# STM32G414xx register map
File version: 1.0
Registers are 32-bit, read-write, reset 0x0 unless marked. A register's access mark holds for its fields unless they carry their own. Offsets are from the block's base; [hi:lo] are bit positions; {n}, {i} and the like mark numbered series.

## CRS — Clock Recovery System
Base 0x40002000
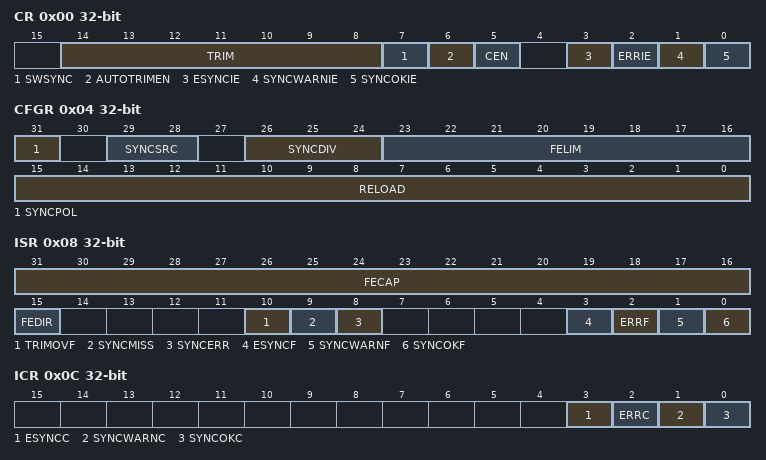
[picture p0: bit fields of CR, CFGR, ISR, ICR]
0x00 CR — CRS ccontrol register
  [14:8] TRIM — HSI48 oscillator smooth trimming
  [7] SWSYNC — Generate software SYNC event
  [6] AUTOTRIMEN — Automatic trimming enable
  [5] CEN — Frequency error counter enable
  [3] ESYNCIE — Expected SYNC interrupt enable
  [2] ERRIE — SYNC error or trimming error interrupt enable
  [1] SYNCWARNIE — SYNC warning interrupt enable
  [0] SYNCOKIE — SYNC event OK interrupt enable
0x04 CFGR — CRS configuration register
  [31] SYNCPOL — SYNC polarity selection
    0=RISING (Synchro Active on rising edge (default)); 1=FALLING (Synchro Active on falling edge)
  [29:28] SYNCSRC — SYNC signal source selection
    0=GPIO (Synchro Signal source GPIO); 1=LSE (Synchro Signal source LSE); 2=USB (Synchro Signal source USB SOF (default))
  [26:24] SYNCDIV — SYNC divider
    0=DIV_1 (Synchro Signal not divided (default)); 1=DIV_2 (Synchro Signal divided by 2); 2=DIV_4 (Synchro Signal divided by 4); 3=DIV_8 (Synchro Signal divided by 8); 4=DIV_16 (Synchro Signal divided by 16); 5=DIV_32 (Synchro Signal divided by 32); 6=DIV_64 (Synchro Signal divided by 64); 7=DIV_128 (Synchro Signal divided by 128)
  [23:16] FELIM — Frequency error limit
  [15:0] RELOAD — Counter reload value
0x08 ISR — CRS interrupt and status register
  [31:16] FECAP — Frequency error capture
  [15] FEDIR — Frequency error direction
    0=UP (Upcounting direction, the actual frequency is above the target); 1=DOWN (Downcounting direction, the actual frequency is below the target)
  [10] TRIMOVF — Trimming overflow or underflow
  [9] SYNCMISS — SYNC missed
  [8] SYNCERR — SYNC error
  [3] ESYNCF — Expected SYNC flag
  [2] ERRF — Error flag
  [1] SYNCWARNF — SYNC warning flag
  [0] SYNCOKF — SYNC event OK flag
0x0C ICR — CRS interrupt flag clear register
  [3] ESYNCC — Expected SYNC clear flag
  [2] ERRC — Error clear flag
  [1] SYNCWARNC — SYNC warning clear flag
  [0] SYNCOKC — SYNC event OK clear flag

## TAMP — Tamper and backup registers
Base 0x40002400
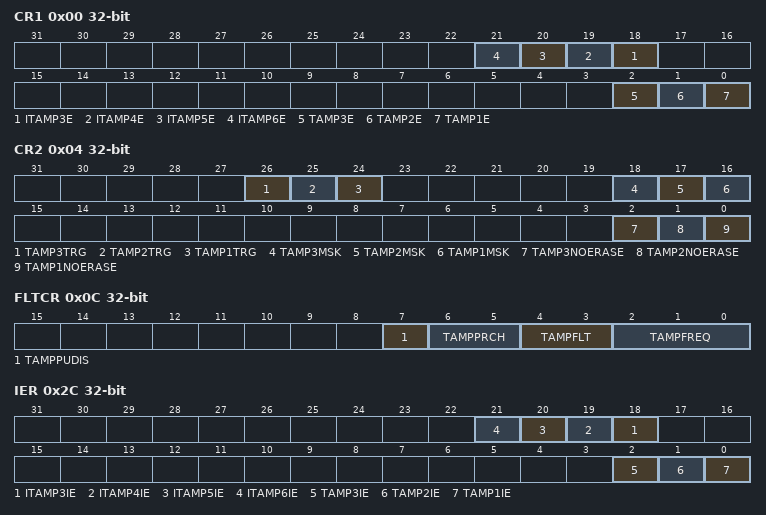
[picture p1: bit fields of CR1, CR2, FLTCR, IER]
0x00 CR1 — TAMP configuration register 1
  [n+15] ITAMP{n}E (n=3..6), [2] TAMP3E, [1] TAMP2E, [0] TAMP1E
0x04 CR2 — TAMP configuration register 2
  [26] TAMP3TRG, [25] TAMP2TRG, [24] TAMP1TRG, [18] TAMP3MSK, [17] TAMP2MSK, [16] TAMP1MSK, [2] TAMP3NOERASE, [1] TAMP2NOERASE, [0] TAMP1NOERASE
0x0C FLTCR — TAMP filter control register
  [7] TAMPPUDIS
  [6:5] TAMPPRCH
    0=DURATION_1RTCCLK (Tamper pins are pre-charged before sampling during 1 RTCCLK cycle); 1=DURATION_2RTCCLK (Tamper pins are pre-charged before sampling during 2 RTCCLK cycles); 2=DURATION_4RTCCLK (Tamper pins are pre-charged before sampling during 4 RTCCLK cycles); 3=DURATION_8RTCCLK (Tamper pins are pre-charged before sampling during 8 RTCCLK cycles)
  [4:3] TAMPFLT
    0=DISABLE (Tamper filter is disabled); 1=FILTER_2SAMPLE (Tamper is activated after 2 consecutive samples at the active level); 2=FILTER_4SAMPLE (Tamper is activated after 4 consecutive samples at the active level); 3=FILTER_8SAMPLE (Tamper is activated after 8 consecutive samples at the active level.)
  [2:0] TAMPFREQ
    0=SAMPLFREQDIV_32768 (Each of the tamper inputs are sampled with a frequency = RTCCLK / 32768); 1=SAMPLFREQDIV_16384 (Each of the tamper inputs are sampled with a frequency = RTCCLK / 16384); 2=SAMPLFREQDIV_8192 (Each of the tamper inputs are sampled with a frequency = RTCCLK / 8192); 3=SAMPLFREQDIV_4096 (Each of the tamper inputs are sampled with a frequency = RTCCLK / 4096); 4=SAMPLFREQDIV_2048 (Each of the tamper inputs are sampled with a frequency = RTCCLK / 2048); 5=SAMPLFREQDIV_1024 (Each of the tamper inputs are sampled with a frequency = RTCCLK / 1024); 6=SAMPLFREQDIV_512 (Each of the tamper inputs are sampled with a frequency = RTCCLK / 512); 7=SAMPLFREQDIV_256 (Each of the tamper inputs are sampled with a frequency = RTCCLK / 256)
0x2C IER — TAMP Interrupt enable register
  [n+15] ITAMP{n}IE (n=3..6), [2] TAMP3IE, [1] TAMP2IE, [0] TAMP1IE
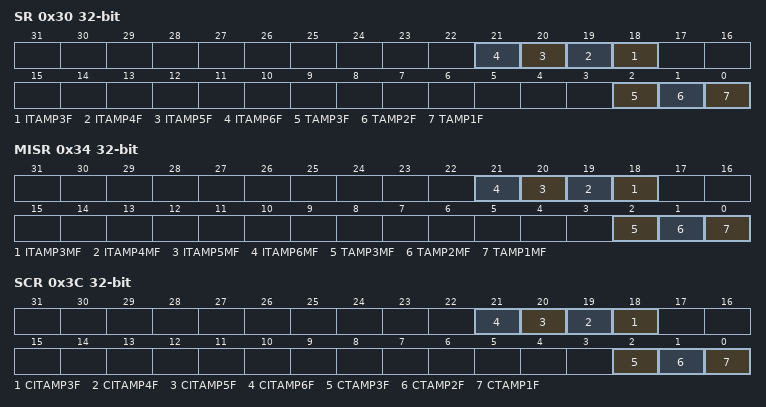
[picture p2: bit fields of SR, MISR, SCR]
0x30 SR — TAMP Status register
  [n+15] ITAMP{n}F (n=3..6), [2] TAMP3F, [1] TAMP2F, [0] TAMP1F
0x34 MISR — TAMP Masked Interrupt Status register
  [n+15] ITAMP{n}MF (n=3..6), [2] TAMP3MF, [1] TAMP2MF, [0] TAMP1MF
0x3C SCR — TAMP Status clear register
  [n+15] CITAMP{n}F (n=3..6), [2] CTAMP3F, [1] CTAMP2F, [0] CTAMP1F
{0x100+4i} BKP{i}R (i=0..31) — TAMP backup register {i}
